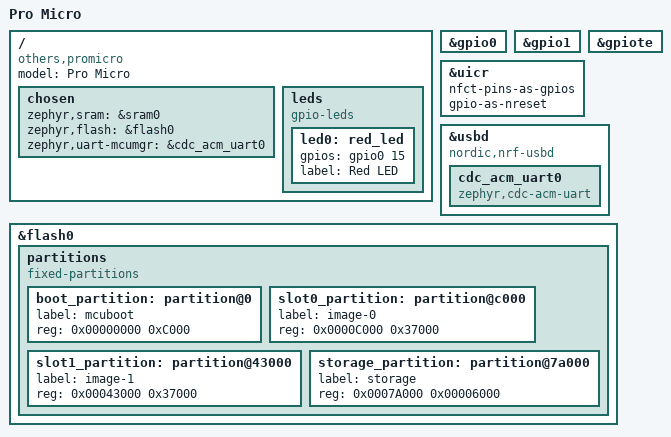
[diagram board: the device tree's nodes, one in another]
/dts-v1/;
#include <nordic/nrf52840_qiaa.dtsi>
#include "promicro_nrf52840-pinctrl.dtsi"
#include <zephyr/dt-bindings/input/input-event-codes.h>

/ {
	model = "Pro Micro";
	compatible = "others,promicro";

	chosen {
		zephyr,sram = &sram0;
		zephyr,flash = &flash0;
		zephyr,uart-mcumgr = &cdc_acm_uart0;
	};

	leds {
		compatible = "gpio-leds";

		led0: red_led {
			gpios = <&gpio0 15 GPIO_ACTIVE_HIGH>;
			label = "Red LED";
		};
	};
};

&gpio0 {
	status = "okay";
};

&gpio1 {
	status = "okay";
};

&gpiote {
	status = "okay";
};

&uicr {
	nfct-pins-as-gpios;
	gpio-as-nreset;
};

zephyr_udc0: &usbd {
	compatible = "nordic,nrf-usbd";
	status = "okay";
};

&zephyr_udc0 {
	cdc_acm_uart0: cdc_acm_uart0 {
		compatible = "zephyr,cdc-acm-uart";
	};
};

&flash0 {
	partitions {
		compatible = "fixed-partitions";
		#address-cells = <1>;
		#size-cells = <1>;

		boot_partition: partition@0 {
			label = "mcuboot";
			reg = <0x00000000 0xC000>;
		};
		slot0_partition: partition@c000 {
			label = "image-0";
			reg = <0x0000C000 0x37000>;
		};
		slot1_partition: partition@43000 {
			label = "image-1";
			reg = <0x00043000 0x37000>;
		};
		storage_partition: partition@7a000 {
			label = "storage";
			reg = <0x0007A000 0x00006000>;
		};
	};
};
